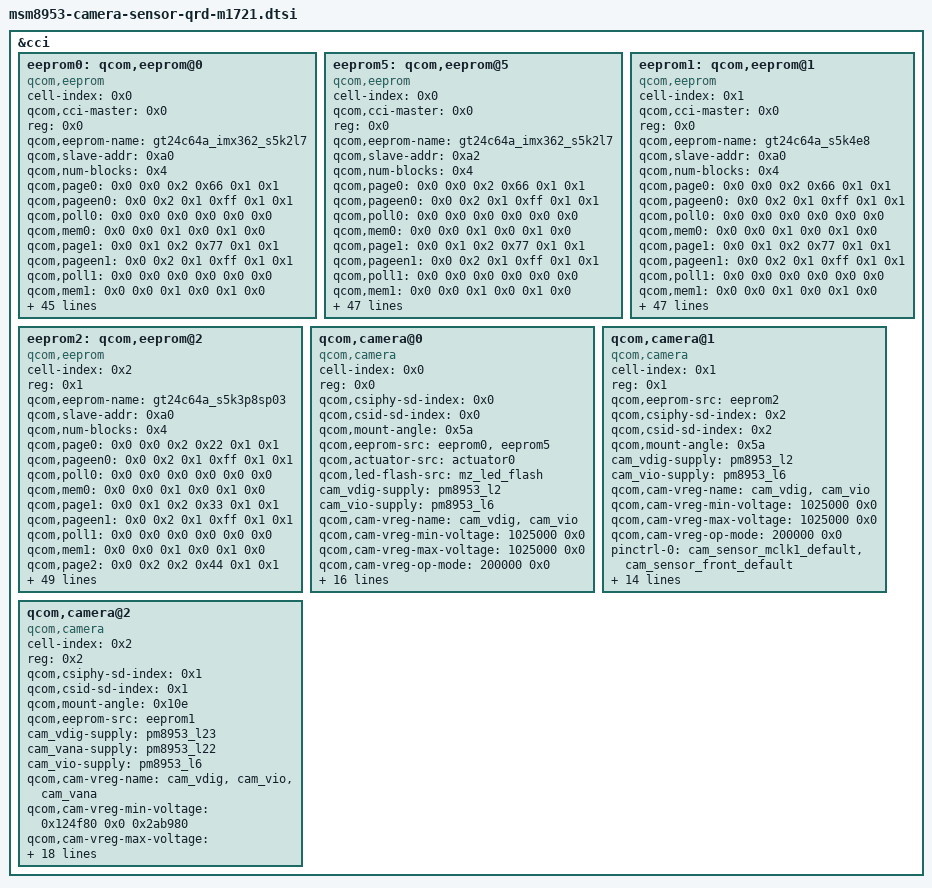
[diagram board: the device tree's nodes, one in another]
/*
 * Copyright (c) 2020, The Linux Foundation. All rights reserved.
 *
 * This program is free software; you can redistribute it and/or modify
 * it under the terms of the GNU General Public License version 2 and
 * only version 2 as published by the Free Software Foundation.
 *
 * This program is distributed in the hope that it will be useful,
 * but WITHOUT ANY WARRANTY; without even the implied warranty of
 * MERCHANTABILITY or FITNESS FOR A PARTICULAR PURPOSE.  See the
 * GNU General Public License for more details.
 */

&cci {
    eeprom0: qcom,eeprom@0 {
        cell-index = <0x0>;
        compatible = "qcom,eeprom";
        qcom,cci-master = <0x0>;
        reg = <0x0>;
        qcom,eeprom-name = "gt24c64a_imx362_s5k2l7";
        qcom,slave-addr = <0xa0>;
        qcom,num-blocks = <0x4>;
        qcom,page0 = <0x0 0x0 0x2 0x66 0x1 0x1>;
        qcom,pageen0 = <0x0 0x2 0x1 0xff 0x1 0x1>;
        qcom,poll0 = <0x0 0x0 0x0 0x0 0x0 0x0>;
        qcom,mem0 = <0x0 0x0 0x1 0x0 0x1 0x0>;
        qcom,page1 = <0x0 0x1 0x2 0x77 0x1 0x1>;
        qcom,pageen1 = <0x0 0x2 0x1 0xff 0x1 0x1>;
        qcom,poll1 = <0x0 0x0 0x0 0x0 0x0 0x0>;
        qcom,mem1 = <0x0 0x0 0x1 0x0 0x1 0x0>;
        qcom,page2 = <0x0 0x2 0x2 0x88 0x1 0x1>;
        qcom,pageen2 = <0x0 0x2 0x1 0xff 0x1 0x1>;
        qcom,poll2 = <0x0 0x0 0x0 0x0 0x0 0x0>;
        qcom,mem2 = <0x0 0x0 0x1 0x0 0x1 0x0>;
        qcom,page3 = <0x0 0x0 0x1 0x55 0x1 0x1>;
        qcom,pageen3 = <0x0 0x2 0x1 0xff 0x1 0x1>;
        qcom,poll3 = <0x0 0x0 0x2 0x0 0x1 0x1>;
        qcom,mem3 = <0x135a 0x0 0x2 0x0 0x1 0x0>;
        qcom,saddr4 = <0xaa>;
        qcom,page4 = <0x0 0x0 0x1 0x99 0x1 0x1>;
        qcom,pageen4 = <0x0 0x2 0x1 0xff 0x1 0x1>;
        qcom,poll4 = <0x0 0x0 0x0 0x0 0x0 0x0>;
        qcom,mem4 = <0xff 0x0 0x1 0x0 0x1 0x0>;
        qcom,saddr5 = <0xac>;
        qcom,page5 = <0x0 0x0 0x1 0x11 0x1 0x1>;
        qcom,pageen5 = <0x0 0x2 0x1 0xff 0x1 0x1>;
        qcom,poll5 = <0x0 0x0 0x0 0x0 0x0 0x0>;
        qcom,mem5 = <0x55 0x0 0x1 0x0 0x1 0x0>;
        cam_vdig-supply = <&pm8953_l2>;
        cam_vio-supply = <&pm8953_l6>;
        qcom,cam-vreg-name = "cam_vdig", "cam_vio";
        qcom,cam-vreg-min-voltage = <1025000 0>;
        qcom,cam-vreg-max-voltage = <1025000 0>;
        qcom,cam-vreg-op-mode = <200000 0>;
        pinctrl-names = "cam_default", "cam_suspend";
        pinctrl-0 = <&cam_sensor_mclk0_default &cam_sensor_rear_default>;
        pinctrl-1 = <&cam_sensor_mclk0_sleep &cam_sensor_rear_sleep>;
        gpios = <&tlmm 26 0x0 &tlmm 40 0x0 &tlmm 17 0x0>;
        qcom,gpio-reset = <1>;
        qcom,gpio-vana = <2>;
        qcom,gpio-req-tbl-num = <0 1 2>;
        qcom,gpio-req-tbl-flags = <1 0 0>;
        qcom,gpio-req-tbl-label = "CAMIF_MCLK0", "CAM_RESET0", "CAM_GPIO_VANA0";
        qcom,cam-power-seq-type = "sensor_gpio", "sensor_gpio", "sensor_vreg", "sensor_vreg", "sensor_gpio", "sensor_clk";
        qcom,cam-power-seq-val = "sensor_gpio_reset", "sensor_gpio_vana", "cam_vdig", "cam_vio", "sensor_gpio_reset", "sensor_cam_mclk";
        qcom,cam-power-seq-cfg-val = <0 1 1 1 1 24000000>;
        qcom,cam-power-seq-delay = <10 10 10 10 10 5>;
        status = "ok";
        clocks = <0x37 0x266b3853 0x37 0x80902deb>;
        clock-names = "cam_src_clk", "cam_clk";
        qcom,clock-rates = <0x16e3600 0x0>;
    };

    eeprom5: qcom,eeprom@5 {
        cell-index = <0x0>;
        compatible = "qcom,eeprom";
        qcom,cci-master = <0x0>;
        reg = <0x0>;
        qcom,eeprom-name = "gt24c64a_imx362_s5k2l7";
        qcom,slave-addr = <0xa2>;
        qcom,num-blocks = <0x4>;
        qcom,page0 = <0x0 0x0 0x2 0x66 0x1 0x1>;
        qcom,pageen0 = <0x0 0x2 0x1 0xff 0x1 0x1>;
        qcom,poll0 = <0x0 0x0 0x0 0x0 0x0 0x0>;
        qcom,mem0 = <0x0 0x0 0x1 0x0 0x1 0x0>;
        qcom,page1 = <0x0 0x1 0x2 0x77 0x1 0x1>;
        qcom,pageen1 = <0x0 0x2 0x1 0xff 0x1 0x1>;
        qcom,poll1 = <0x0 0x0 0x0 0x0 0x0 0x0>;
        qcom,mem1 = <0x0 0x0 0x1 0x0 0x1 0x0>;
        qcom,page2 = <0x0 0x2 0x2 0x88 0x1 0x1>;
        qcom,pageen2 = <0x0 0x2 0x1 0xff 0x1 0x1>;
        qcom,poll2 = <0x0 0x0 0x0 0x0 0x0 0x0>;
        qcom,mem2 = <0x0 0x0 0x1 0x0 0x1 0x0>;
        qcom,page3 = <0x0 0x0 0x1 0x55 0x1 0x1>;
        qcom,pageen3 = <0x0 0x2 0x1 0xff 0x1 0x1>;
        qcom,poll3 = <0x0 0x0 0x2 0x0 0x1 0x1>;
        qcom,mem3 = <0x1d90 0x0 0x2 0x0 0x1 0x0>;
        qcom,saddr4 = <0xaa>;
        qcom,page4 = <0x0 0x0 0x1 0x99 0x1 0x1>;
        qcom,pageen4 = <0x0 0x2 0x1 0xff 0x1 0x1>;
        qcom,poll4 = <0x0 0x0 0x0 0x0 0x0 0x0>;
        qcom,mem4 = <0xff 0x0 0x1 0x0 0x1 0x0>;
        qcom,saddr5 = <0xac>;
        qcom,page5 = <0x0 0x0 0x1 0x11 0x1 0x1>;
        qcom,pageen5 = <0x0 0x2 0x1 0xff 0x1 0x1>;
        qcom,poll5 = <0x0 0x0 0x0 0x0 0x0 0x0>;
        qcom,mem5 = <0x55 0x0 0x1 0x0 0x1 0x0>;
        cam_vdig-supply = <&pm8953_l2>;
        cam_vio-supply = <&pm8953_l6>;
        qcom,cam-vreg-name = "cam_vdig", "cam_vio";
        qcom,cam-vreg-min-voltage = <1025000 0x0>;
        qcom,cam-vreg-max-voltage = <1025000 0x0>;
        qcom,cam-vreg-op-mode = <200000 0x0>;
        pinctrl-names = "cam_default", "cam_suspend";
        pinctrl-0 = <&cam_sensor_mclk0_default &cam_sensor_rear_default>;
        pinctrl-1 = <&cam_sensor_mclk0_sleep &cam_sensor_rear_sleep>;
        gpios = <&tlmm 0x1a 0x0 &tlmm 0x28 0x0 &tlmm 0x11 0x0>;
        qcom,gpio-reset = <0x1>;
        qcom,gpio-vana = <0x2>;
        qcom,gpio-req-tbl-num = <0x0 0x1 0x2>;
        qcom,gpio-req-tbl-flags = <0x1 0x0 0x0>;
        qcom,gpio-req-tbl-label = "CAMIF_MCLK0", "CAM_RESET0", "CAM_GPIO_VANA0";
        qcom,cam-power-seq-type = "sensor_gpio", "sensor_gpio", "sensor_vreg", "sensor_vreg", "sensor_gpio", "sensor_clk";
        qcom,cam-power-seq-val = "sensor_gpio_reset", "sensor_gpio_vana", "cam_vdig", "cam_vio", "sensor_gpio_reset", "sensor_cam_mclk";
        qcom,cam-power-seq-cfg-val = <0x0 0x1 0x1 0x1 0x1 0x16e3600>;
        qcom,cam-power-seq-delay = <0xa 0xa 0xa 0xa 0xa 0x5>;
        status = "ok";
        clocks = <0x37 0x266b3853 0x37 0x80902deb>;
        clock-names = "cam_src_clk", "cam_clk";
        qcom,clock-rates = <0x16e3600 0x0>;
    };

    eeprom1: qcom,eeprom@1 {
        cell-index = <0x1>;
        compatible = "qcom,eeprom";
        qcom,cci-master = <0x0>;
        reg = <0x0>;
        qcom,eeprom-name = "gt24c64a_s5k4e8";
        qcom,slave-addr = <0xa0>;
        qcom,num-blocks = <0x4>;
        qcom,page0 = <0x0 0x0 0x2 0x66 0x1 0x1>;
        qcom,pageen0 = <0x0 0x2 0x1 0xff 0x1 0x1>;
        qcom,poll0 = <0x0 0x0 0x0 0x0 0x0 0x0>;
        qcom,mem0 = <0x0 0x0 0x1 0x0 0x1 0x0>;
        qcom,page1 = <0x0 0x1 0x2 0x77 0x1 0x1>;
        qcom,pageen1 = <0x0 0x2 0x1 0xff 0x1 0x1>;
        qcom,poll1 = <0x0 0x0 0x0 0x0 0x0 0x0>;
        qcom,mem1 = <0x0 0x0 0x1 0x0 0x1 0x0>;
        qcom,page2 = <0x0 0x2 0x2 0x88 0x1 0x1>;
        qcom,pageen2 = <0x0 0x2 0x1 0xff 0x1 0x1>;
        qcom,poll2 = <0x0 0x0 0x0 0x0 0x0 0x0>;
        qcom,mem2 = <0x0 0x0 0x1 0x0 0x1 0x0>;
        qcom,page3 = <0x0 0x0 0x1 0x55 0x1 0x1>;
        qcom,pageen3 = <0x0 0x2 0x1 0xff 0x1 0x1>;
        qcom,poll3 = <0x0 0x0 0x2 0x0 0x1 0x1>;
        qcom,mem3 = <0x1a6c 0x0 0x2 0x0 0x1 0x0>;
        qcom,saddr4 = <0xaa>;
        qcom,page4 = <0x0 0x0 0x1 0x99 0x1 0x1>;
        qcom,pageen4 = <0x0 0x2 0x1 0xff 0x1 0x1>;
        qcom,poll4 = <0x0 0x0 0x0 0x0 0x0 0x0>;
        qcom,mem4 = <0xff 0x0 0x1 0x0 0x1 0x0>;
        qcom,saddr5 = <0xac>;
        qcom,page5 = <0x0 0x0 0x1 0x11 0x1 0x1>;
        qcom,pageen5 = <0x0 0x2 0x1 0xff 0x1 0x1>;
        qcom,poll5 = <0x0 0x0 0x0 0x0 0x0 0x0>;
        qcom,mem5 = <0x55 0x0 0x1 0x0 0x1 0x0>;
        cam_vdig-supply = <&pm8953_l2>;
        cam_vio-supply = <&pm8953_l6>;
        qcom,cam-vreg-name = "cam_vdig", "cam_vio";
        qcom,cam-vreg-min-voltage = <1025000 0x0>;
        qcom,cam-vreg-max-voltage = <1025000 0x0>;
        qcom,cam-vreg-op-mode = <200000 0x0>;
        pinctrl-names = "cam_default", "cam_suspend";
        pinctrl-0 = <&cam_sensor_mclk0_default &cam_sensor_rear_default>;
        pinctrl-1 = <&cam_sensor_mclk0_sleep &cam_sensor_rear_sleep>;
        gpios = <&tlmm 0x1a 0x0 &tlmm 0x28 0x0 &tlmm 0x11 0x0>;
        qcom,gpio-reset = <0x1>;
        qcom,gpio-vana = <0x2>;
        qcom,gpio-req-tbl-num = <0x0 0x1 0x2>;
        qcom,gpio-req-tbl-flags = <0x1 0x0 0x0>;
        qcom,gpio-req-tbl-label = "CAMIF_MCLK0", "CAM_RESET0", "CAM_GPIO_VANA0";
        qcom,cam-power-seq-type = "sensor_gpio", "sensor_gpio", "sensor_vreg", "sensor_vreg", "sensor_gpio", "sensor_clk";
        qcom,cam-power-seq-val = "sensor_gpio_reset", "sensor_gpio_vana", "cam_vdig", "cam_vio", "sensor_gpio_reset", "sensor_cam_mclk";
        qcom,cam-power-seq-cfg-val = <0x0 0x1 0x1 0x1 0x1 0x16e3600>;
        qcom,cam-power-seq-delay = <0xa 0xa 0xa 0xa 0xa 0x5>;
        status = "ok";
        clocks = <0x37 0x266b3853 0x37 0x80902deb>;
        clock-names = "cam_src_clk", "cam_clk";
        qcom,clock-rates = <0x16e3600 0x0>;
    };

    eeprom2: qcom,eeprom@2 {
        cell-index = <0x2>;
        reg = <0x1>;
        compatible = "qcom,eeprom";
        qcom,eeprom-name = "gt24c64a_s5k3p8sp03";
        qcom,slave-addr = <0xa0>;
        qcom,num-blocks = <0x4>;
        qcom,page0 = <0x0 0x0 0x2 0x22 0x1 0x1>;
        qcom,pageen0 = <0x0 0x2 0x1 0xff 0x1 0x1>;
        qcom,poll0 = <0x0 0x0 0x0 0x0 0x0 0x0>;
        qcom,mem0 = <0x0 0x0 0x1 0x0 0x1 0x0>;
        qcom,page1 = <0x0 0x1 0x2 0x33 0x1 0x1>;
        qcom,pageen1 = <0x0 0x2 0x1 0xff 0x1 0x1>;
        qcom,poll1 = <0x0 0x0 0x0 0x0 0x0 0x0>;
        qcom,mem1 = <0x0 0x0 0x1 0x0 0x1 0x0>;
        qcom,page2 = <0x0 0x2 0x2 0x44 0x1 0x1>;
        qcom,pageen2 = <0x0 0x2 0x1 0xff 0x1 0x1>;
        qcom,poll2 = <0x0 0x0 0x0 0x0 0x0 0x0>;
        qcom,mem2 = <0x0 0x0 0x1 0x0 0x1 0x0>;
        qcom,page3 = <0x0 0x0 0x1 0x55 0x1 0x1>;
        qcom,pageen3 = <0x0 0x2 0x1 0xff 0x1 0x1>;
        qcom,poll3 = <0x0 0x0 0x2 0x0 0x1 0x1>;
        qcom,mem3 = <0xf40 0x0 0x2 0x0 0x1 0x0>;
        qcom,saddr4 = <0xaa>;
        qcom,page4 = <0x0 0x0 0x1 0x99 0x1 0x1>;
        qcom,pageen4 = <0x0 0x2 0x1 0xff 0x1 0x1>;
        qcom,poll4 = <0x0 0x0 0x0 0x0 0x0 0x0>;
        qcom,mem4 = <0xff 0x0 0x1 0x0 0x1 0x0>;
        qcom,saddr5 = <0xac>;
        qcom,page5 = <0x0 0x0 0x1 0x11 0x1 0x1>;
        qcom,pageen5 = <0x0 0x2 0x1 0xff 0x1 0x1>;
        qcom,poll5 = <0x0 0x0 0x0 0x0 0x0 0x0>;
        qcom,mem5 = <0x55 0x0 0x1 0x0 0x1 0x0>;
        cam_vdig-supply = <&pm8953_l2>;
        cam_vio-supply = <&pm8953_l6>;
        qcom,cam-vreg-name = "cam_vdig", "cam_vio";
        qcom,cam-vreg-min-voltage = <1025000 0x0>;
        qcom,cam-vreg-max-voltage = <1025000 0x0>;
        qcom,cam-vreg-op-mode = <200000 0x0>;
        pinctrl-names = "cam_default", "cam_suspend";
        pinctrl-0 = <&cam_sensor_mclk1_default &cam_sensor_front_default>;
        pinctrl-1 = <&cam_sensor_mclk1_sleep &cam_sensor_front_sleep>;
        gpios = <&tlmm 0x1b 0x0 &tlmm 0x81 0x0 &tlmm 0x24 0x0>;
        qcom,gpio-reset = <0x1>;
        qcom,gpio-vana = <0x2>;
        qcom,gpio-req-tbl-num = <0x0 0x1 0x2>;
        qcom,gpio-req-tbl-flags = <0x1 0x0 0x0>;
        qcom,gpio-req-tbl-label = "CAMIF_MCLK1", "CAM_RESET1", "CAM_GPIO_VANA1";
        qcom,sensor-position = <0x4>;
        qcom,sensor-mode = <0x0>;
        qcom,cci-master = <0x1>;
        qcom,cam-power-seq-type = "sensor_gpio", "sensor_gpio", "sensor_vreg", "sensor_vreg", "sensor_gpio", "sensor_clk";
        qcom,cam-power-seq-val = "sensor_gpio_reset", "sensor_gpio_vana", "cam_vio", "cam_vdig", "sensor_gpio_reset", "sensor_cam_mclk";
        qcom,cam-power-seq-cfg-val = <0x0 0x1 0x1 0x1 0x1 0x16e3600>;
        qcom,cam-power-seq-delay = <0xa 0xa 0xa 0xa 0xa 0x5>;
        status = "ok";
        clocks = <0x37 0xa73cad0c 0x37 0x5002d85f>;
        clock-names = "cam_src_clk", "cam_clk";
        qcom,clock-rates = <0x16e3600 0x0>;
    };

    qcom,camera@0 {
        cell-index = <0x0>;
        compatible = "qcom,camera";
        reg = <0x0>;
        qcom,csiphy-sd-index = <0x0>;
        qcom,csid-sd-index = <0x0>;
        qcom,mount-angle = <0x5a>;
        qcom,eeprom-src = <&eeprom0 &eeprom5>;
        qcom,actuator-src = <&actuator0>;
        qcom,led-flash-src = <&mz_led_flash>;
        cam_vdig-supply = <&pm8953_l2>;
        cam_vio-supply = <&pm8953_l6>;
        qcom,cam-vreg-name = "cam_vdig", "cam_vio";
        qcom,cam-vreg-min-voltage = <1025000 0x0>;
        qcom,cam-vreg-max-voltage = <1025000 0x0>;
        qcom,cam-vreg-op-mode = <200000 0x0>;
        pinctrl-names = "cam_default", "cam_suspend";
        pinctrl-0 = <&cam_sensor_mclk0_default &cam_sensor_rear_default>;
        pinctrl-1 = <&cam_sensor_mclk0_sleep &cam_sensor_rear_sleep>;
        gpios = <&tlmm 0x1a 0x0 &tlmm 0x28 0x0 &tlmm 0x11 0x0>;
        qcom,gpio-reset = <0x1>;
        qcom,gpio-vana = <0x2>;
        qcom,gpio-req-tbl-num = <0x0 0x1 0x2>;
        qcom,gpio-req-tbl-flags = <0x1 0x0 0x0>;
        qcom,gpio-req-tbl-label = "CAMIF_MCLK0", "CAM_RESET0", "CAM_GPIO_VANA0";
        qcom,sensor-position = <0x0>;
        qcom,sensor-mode = <0x0>;
        qcom,cci-master = <0x0>;
        status = "ok";
        clocks = <0x37 0x266b3853 0x37 0x80902deb>;
        clock-names = "cam_src_clk", "cam_clk";
        qcom,clock-rates = <0x16e3600 0x0>;
    };

    qcom,camera@1 {
        cell-index = <0x1>;
        compatible = "qcom,camera";
        reg = <0x1>;
        qcom,eeprom-src = <&eeprom2>;
        qcom,csiphy-sd-index = <0x2>;
        qcom,csid-sd-index = <0x2>;
        qcom,mount-angle = <0x5a>;
        cam_vdig-supply = <&pm8953_l2>;
        cam_vio-supply = <&pm8953_l6>;
        qcom,cam-vreg-name = "cam_vdig", "cam_vio";
        qcom,cam-vreg-min-voltage = <1025000 0x0>;
        qcom,cam-vreg-max-voltage = <1025000 0x0>;
        qcom,cam-vreg-op-mode = <200000 0x0>;
        pinctrl-names = "cam_default", "cam_suspend";
        pinctrl-0 = <&cam_sensor_mclk1_default &cam_sensor_front_default>;
        pinctrl-1 = <&cam_sensor_mclk1_sleep &cam_sensor_front_sleep>;
        gpios = <&tlmm 0x1b 0x0 &tlmm 0x81 0x0 &tlmm 0x24 0x0>;
        qcom,gpio-reset = <0x1>;
        qcom,gpio-vana = <0x2>;
        qcom,gpio-req-tbl-num = <0x0 0x1 0x2>;
        qcom,gpio-req-tbl-flags = <0x1 0x0 0x0>;
        qcom,gpio-req-tbl-label = "CAMIF_MCLK1", "CAM_RESET1", "CAM_GPIO_VANA1";
        qcom,sensor-position = <0x4>;
        qcom,sensor-mode = <0x0>;
        qcom,cci-master = <0x1>;
        status = "ok";
        clocks = <0x37 0xa73cad0c 0x37 0x5002d85f>;
        clock-names = "cam_src_clk", "cam_clk";
        qcom,clock-rates = <0x16e3600 0x0>;
    };

    qcom,camera@2 {
        cell-index = <0x2>;
        compatible = "qcom,camera";
        reg = <0x2>;
        qcom,csiphy-sd-index = <0x1>;
        qcom,csid-sd-index = <0x1>;
        qcom,mount-angle = <0x10e>;
        qcom,eeprom-src = <&eeprom1>;
        cam_vdig-supply = <&pm8953_l23>;
        cam_vana-supply = <&pm8953_l22>;
        cam_vio-supply = <&pm8953_l6>;
        qcom,cam-vreg-name = "cam_vdig", "cam_vio", "cam_vana";
        qcom,cam-vreg-min-voltage = <0x124f80 0x0 0x2ab980>;
        qcom,cam-vreg-max-voltage = <0x124f80 0x0 0x2ab980>;
        qcom,cam-vreg-op-mode = <0x19a28 0x0 0x13880>;
        qcom,gpio-no-mux = <0x0>;
        pinctrl-names = "cam_default", "cam_suspend";
        pinctrl-0 = <&cam_sensor_mclk2_default &cam_sensor_front1_default>;
        pinctrl-1 = <&cam_sensor_mclk2_sleep &cam_sensor_front1_sleep>;
        gpios = <&tlmm 0x1c 0x0 &tlmm 0x83 0x0>;
        qcom,gpio-reset = <0x1>;
        qcom,gpio-req-tbl-num = <0x0 0x1>;
        qcom,gpio-req-tbl-flags = <0x1 0x0>;
        qcom,gpio-req-tbl-label = "CAMIF_MCLK2", "CAM_RESET2";
        qcom,sensor-position = <0x2>;
        qcom,sensor-mode = <0x0>;
        qcom,cci-master = <0x1>;
        status = "ok";
        clocks = <0x37 0x42545468 0x37 0x222f8fff>;
        clock-names = "cam_src_clk", "cam_clk";
        qcom,clock-rates = <0x16e3600 0x0>;
    };
};
